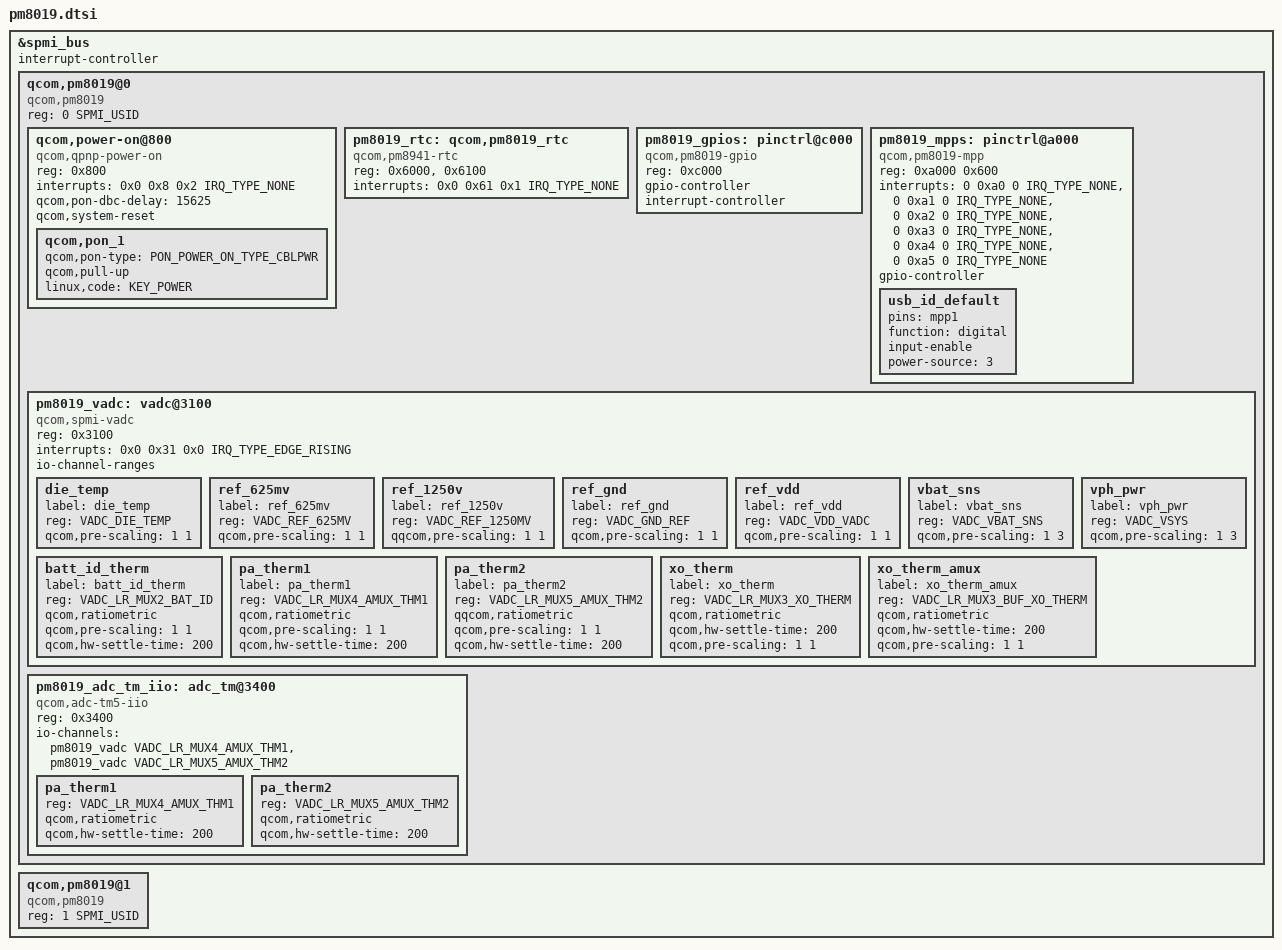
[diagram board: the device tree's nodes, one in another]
#include <dt-bindings/input/input.h>
#include <dt-bindings/input/qcom,qpnp-power-on.h>
#include <dt-bindings/interrupt-controller/irq.h>
#include <dt-bindings/spmi/spmi.h>
#include <dt-bindings/iio/qcom,spmi-vadc.h>

&spmi_bus {
	#address-cells = <2>;
	#size-cells = <0>;
	interrupt-controller;
	#interrupt-cells = <4>;

	qcom,pm8019@0 {
		compatible = "qcom,pm8019";
		reg = <0 SPMI_USID>;
		#address-cells = <1>;
		#size-cells = <0>;

		qcom,power-on@800 {
			compatible = "qcom,qpnp-power-on";
			reg = <0x800>;
			interrupts = <0x0 0x8 0x2 IRQ_TYPE_NONE>;
			interrupt-names = "cblpwr";
			qcom,pon-dbc-delay = <15625>;
			qcom,system-reset;

			qcom,pon_1 {
				qcom,pon-type = <PON_POWER_ON_TYPE_CBLPWR>;
				qcom,pull-up;
				linux,code = <KEY_POWER>;
			};
		};

		pm8019_rtc: qcom,pm8019_rtc {
			compatible = "qcom,pm8941-rtc";
			reg = <0x6000>, <0x6100>;
			reg-names = "rtc", "alarm";
			interrupts = <0x0 0x61 0x1 IRQ_TYPE_NONE>;
		};

		pm8019_gpios: pinctrl@c000 {
			compatible = "qcom,pm8019-gpio";
			reg = <0xc000>;
			gpio-controller;
			#gpio-cells = <2>;
			interrupt-controller;
			#interrupt-cells = <2>;
		};

		pm8019_mpps: pinctrl@a000 {
			compatible = "qcom,pm8019-mpp";
			reg = <0xa000 0x600>;
			interrupts = <0 0xa0 0 IRQ_TYPE_NONE>,
					<0 0xa1 0 IRQ_TYPE_NONE>,
					<0 0xa2 0 IRQ_TYPE_NONE>,
					<0 0xa3 0 IRQ_TYPE_NONE>,
					<0 0xa4 0 IRQ_TYPE_NONE>,
					<0 0xa5 0 IRQ_TYPE_NONE>;
			interrupt-names = "pm8019_mpp1", "pm8019_mpp2",
					  "pm8019_mpp3", "pm8019_mpp4",
					  "pm8019_mpp5", "pm8019_mpp6";
			gpio-controller;
			#gpio-cells = <2>;

			/* MPP pin 1 config for USB ID interrupt line */
			usb_id_default: usb_id_default {
				pins = "mpp1";
				function = "digital";
				input-enable;
				power-source = <3>;
			};
		};

		pm8019_vadc: vadc@3100 {
			compatible = "qcom,spmi-vadc";
			reg = <0x3100>;
			#address-cells = <1>;
			#size-cells = <0>;
			interrupts = <0x0 0x31 0x0 IRQ_TYPE_EDGE_RISING>;
			interrupt-names = "eoc-int-en-set";
			#io-channel-cells = <1>;
			io-channel-ranges;

			die_temp {
				label = "die_temp";
				reg = <VADC_DIE_TEMP>;
				qcom,pre-scaling = <1 1>;
			};

			ref_625mv {
				label = "ref_625mv";
				reg = <VADC_REF_625MV>;
				qcom,pre-scaling = <1 1>;
			};

			ref_1250v {
				label = "ref_1250v";
				reg = <VADC_REF_1250MV>;
				qqcom,pre-scaling = <1 1>;
			};

			ref_gnd {
				label = "ref_gnd";
				reg = <VADC_GND_REF>;
				qcom,pre-scaling = <1 1>;
			};

			ref_vdd {
				label = "ref_vdd";
				reg = <VADC_VDD_VADC>;
				qcom,pre-scaling = <1 1>;
			};

			vbat_sns {
				label = "vbat_sns";
				reg = <VADC_VBAT_SNS>;
				qcom,pre-scaling = <1 3>;
			};

			vph_pwr {
				label = "vph_pwr";
				reg = <VADC_VSYS>;
				qcom,pre-scaling = <1 3>;
			};

			batt_id_therm {
				label = "batt_id_therm";
				reg = <VADC_LR_MUX2_BAT_ID>;
				qcom,ratiometric;
				qcom,pre-scaling = <1 1>;
				qcom,hw-settle-time = <200>;
			};

			pa_therm1 {
				label = "pa_therm1";
				reg = <VADC_LR_MUX4_AMUX_THM1>;
				qcom,ratiometric;
				qcom,pre-scaling = <1 1>;
				qcom,hw-settle-time = <200>;
			};

			pa_therm2 {
				label = "pa_therm2";
				reg = <VADC_LR_MUX5_AMUX_THM2>;
				qqcom,ratiometric;
				qcom,pre-scaling = <1 1>;
				qcom,hw-settle-time = <200>;
			};

			xo_therm {
				label = "xo_therm";
				reg = <VADC_LR_MUX3_XO_THERM>;
				qcom,ratiometric;
				qcom,hw-settle-time = <200>;
				qcom,pre-scaling = <1 1>;
			};

			xo_therm_amux {
				label = "xo_therm_amux";
				reg = <VADC_LR_MUX3_BUF_XO_THERM>;
				qcom,ratiometric;
				qcom,hw-settle-time = <200>;
				qcom,pre-scaling = <1 1>;
			};
		};

		pm8019_adc_tm_iio: adc_tm@3400 {
			compatible = "qcom,adc-tm5-iio";
			reg = <0x3400>;
			#address-cells = <1>;
			#size-cells = <0>;
			#thermal-sensor-cells = <1>;
			io-channels = <&pm8019_vadc VADC_LR_MUX4_AMUX_THM1>,
					<&pm8019_vadc VADC_LR_MUX5_AMUX_THM2>;

			pa_therm1 {
				reg = <VADC_LR_MUX4_AMUX_THM1>;
				qcom,ratiometric;
				qcom,hw-settle-time = <200>;
			};

			pa_therm2 {
				reg = <VADC_LR_MUX5_AMUX_THM2>;
				qcom,ratiometric;
				qcom,hw-settle-time = <200>;
			};
		};
	};

	qcom,pm8019@1 {
		compatible = "qcom,pm8019";
		reg = <1 SPMI_USID>;
		#address-cells = <1>;
		#size-cells = <0>;
	};
};
